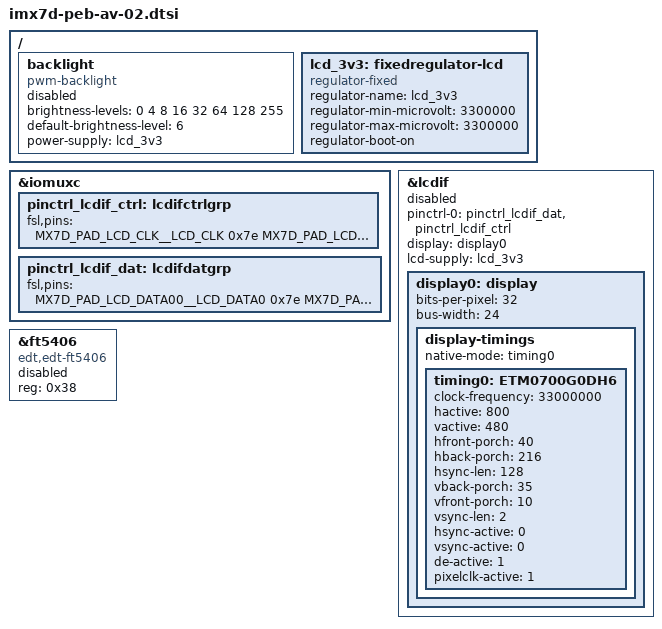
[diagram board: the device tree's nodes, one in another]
/*
 * Copyright (C) 2015 PHYTEC America, LLC
 *
 * This program is free software; you can redistribute it and/or modify
 * it under the terms of the GNU General Public License version 2 as
 * published by the Free Software Foundation.
 */

/ {
	backlight: backlight {
		compatible = "pwm-backlight";
		brightness-levels = <0 4 8 16 32 64 128 255>;
		default-brightness-level = <6>;
		power-supply = <&lcd_3v3>;
		status = "disabled";
	};

	lcd_3v3: fixedregulator-lcd {
		compatible = "regulator-fixed";
		regulator-name = "lcd_3v3";
		regulator-min-microvolt = <3300000>;
		regulator-max-microvolt = <3300000>;
		regulator-boot-on;
	};
};

&iomuxc {
	pinctrl_lcdif_ctrl: lcdifctrlgrp {
		fsl,pins = <
			MX7D_PAD_LCD_CLK__LCD_CLK	0x7e
			MX7D_PAD_LCD_ENABLE__LCD_ENABLE	0x7e
			MX7D_PAD_LCD_HSYNC__LCD_HSYNC	0x7e
			MX7D_PAD_LCD_VSYNC__LCD_VSYNC	0x7e
		>;
	};

	pinctrl_lcdif_dat: lcdifdatgrp {
		fsl,pins = <
			MX7D_PAD_LCD_DATA00__LCD_DATA0	0x7e
			MX7D_PAD_LCD_DATA01__LCD_DATA1	0x7e
			MX7D_PAD_LCD_DATA02__LCD_DATA2	0x7e
			MX7D_PAD_LCD_DATA03__LCD_DATA3	0x7e
			MX7D_PAD_LCD_DATA04__LCD_DATA4	0x7e
			MX7D_PAD_LCD_DATA05__LCD_DATA5	0x7e
			MX7D_PAD_LCD_DATA06__LCD_DATA6	0x7e
			MX7D_PAD_LCD_DATA07__LCD_DATA7	0x7e
			MX7D_PAD_LCD_DATA08__LCD_DATA8	0x7e
			MX7D_PAD_LCD_DATA09__LCD_DATA9	0x7e
			MX7D_PAD_LCD_DATA10__LCD_DATA10	0x7e
			MX7D_PAD_LCD_DATA11__LCD_DATA11	0x7e
			MX7D_PAD_LCD_DATA12__LCD_DATA12	0x7e
			MX7D_PAD_LCD_DATA13__LCD_DATA13	0x7e
			MX7D_PAD_LCD_DATA14__LCD_DATA14	0x7e
			MX7D_PAD_LCD_DATA15__LCD_DATA15	0x7e
			MX7D_PAD_LCD_DATA16__LCD_DATA16	0x7e
			MX7D_PAD_LCD_DATA17__LCD_DATA17	0x7e
			MX7D_PAD_LCD_DATA18__LCD_DATA18	0x7e
			MX7D_PAD_LCD_DATA19__LCD_DATA19	0x7e
			MX7D_PAD_LCD_DATA20__LCD_DATA20	0x7e
			MX7D_PAD_LCD_DATA21__LCD_DATA21	0x7e
			MX7D_PAD_LCD_DATA22__LCD_DATA22	0x7e
			MX7D_PAD_LCD_DATA23__LCD_DATA23	0x7e
		>;
	};
};

&lcdif {
	pinctrl-names = "default";
	pinctrl-0 = <&pinctrl_lcdif_dat
		&pinctrl_lcdif_ctrl>;
	display = <&display0>;
	lcd-supply = <&lcd_3v3>;
	status = "disabled";

	display0: display {
		bits-per-pixel = <32>;
		bus-width = <24>;

		display-timings {
			native-mode = <&timing0>;
			timing0: ETM0700G0DH6 {
				clock-frequency = <33000000>;
				hactive = <800>;
				vactive = <480>;
				hfront-porch = <40>;
				hback-porch = <216>;
				hsync-len = <128>;
				vback-porch = <35>;
				vfront-porch = <10>;
				vsync-len = <2>;
				hsync-active = <0>;
				vsync-active = <0>;
				de-active = <1>;
				pixelclk-active = <1>;
			};
		};
	};
};

&ft5406 {
	compatible = "edt,edt-ft5406", "edt,edt-ft5x06";
	reg = <0x38>;
	status = "disabled";
};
